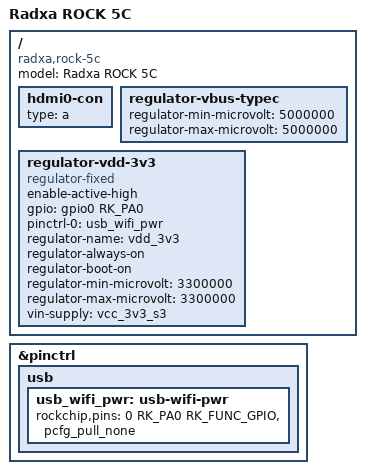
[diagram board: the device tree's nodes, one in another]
// SPDX-License-Identifier: (GPL-2.0+ OR MIT)
/*
 * Copyright (c) 2024 Radxa Computer (Shenzhen) Co., Ltd.
 */

/dts-v1/;

#include "rk3588s-rock-5.dtsi"

/ {
	model = "Radxa ROCK 5C";
	compatible = "radxa,rock-5c", "rockchip,rk3588s";

	hdmi0-con {
		type = "a";
	};

	regulator-vbus-typec {
		regulator-min-microvolt = <5000000>;
		regulator-max-microvolt = <5000000>;
	};

	regulator-vdd-3v3 {
		compatible = "regulator-fixed";
		enable-active-high;
		gpio = <&gpio0 RK_PA0 GPIO_ACTIVE_HIGH>;
		pinctrl-names = "default";
		pinctrl-0 = <&usb_wifi_pwr>;
		regulator-name = "vdd_3v3";
		regulator-always-on;
		regulator-boot-on;
		regulator-min-microvolt = <3300000>;
		regulator-max-microvolt = <3300000>;
		vin-supply = <&vcc_3v3_s3>;
	};
};

&pinctrl {
	usb {
		usb_wifi_pwr: usb-wifi-pwr {
			rockchip,pins = <0 RK_PA0 RK_FUNC_GPIO &pcfg_pull_none>;
		};
	};
};
